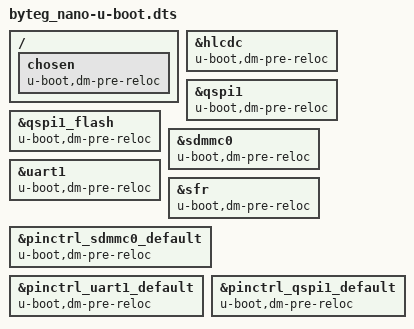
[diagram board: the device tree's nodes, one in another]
// SPDX-License-Identifier: (GPL-2.0+ OR MIT)
/*
 * byteg_nano-u-boot.dts - Device Tree file for SAMA5D27 BYTEG NANO
 *
 * Copyright (C) 2019 Microchip Technology Inc. and its subsidiaries
 *
 * Author: Jordan Ovrè
 */

/ {
	chosen {
		u-boot,dm-pre-reloc;
	};
};

&hlcdc {
	u-boot,dm-pre-reloc;
};

&qspi1 {
	u-boot,dm-pre-reloc;
};

&qspi1_flash {
	u-boot,dm-pre-reloc;
};

&sdmmc0 {
	u-boot,dm-pre-reloc;
};

&uart1 {
	u-boot,dm-pre-reloc;
};

&sfr {
	u-boot,dm-pre-reloc;
};

&pinctrl_sdmmc0_default {
	u-boot,dm-pre-reloc;
};

&pinctrl_uart1_default {
	u-boot,dm-pre-reloc;
};

&pinctrl_qspi1_default {
	u-boot,dm-pre-reloc;
};
